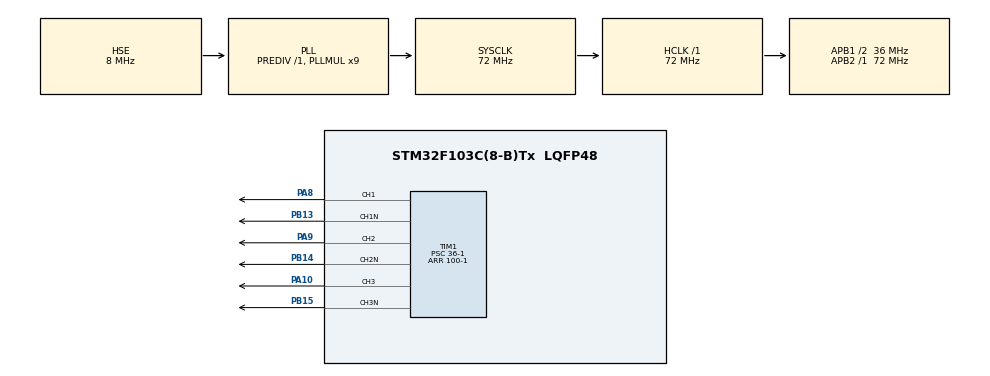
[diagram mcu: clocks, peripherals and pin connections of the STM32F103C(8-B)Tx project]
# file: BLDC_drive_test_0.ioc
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Mcu.Family=STM32F1
Mcu.Name=STM32F103C(8-B)Tx
Mcu.Package=LQFP48
NVIC.PriorityGroup=NVIC_PRIORITYGROUP_4
PA10.Signal=S_TIM1_CH3
PA8.Signal=S_TIM1_CH1
PA9.Signal=S_TIM1_CH2
PB13.Mode=PWM Generation1 CH1 CH1N
PB13.Signal=TIM1_CH1N
PB14.Mode=PWM Generation2 CH2 CH2N
PB14.Signal=TIM1_CH2N
PB15.Mode=PWM Generation3 CH3 CH3N
PB15.Signal=TIM1_CH3N
PD0-OSC_IN.Mode=HSE-External-Oscillator
PD0-OSC_IN.Signal=RCC_OSC_IN
PD1-OSC_OUT.Mode=HSE-External-Oscillator
PD1-OSC_OUT.Signal=RCC_OSC_OUT
ProjectManager.HeapSize=0x200
ProjectManager.StackSize=0x400
ProjectManager.TargetToolchain=MDK-ARM V5
RCC.AHBFreq_Value=72000000
RCC.APB1CLKDivider=RCC_HCLK_DIV2
RCC.APB1Freq_Value=36000000
RCC.APB1TimFreq_Value=72000000
RCC.APB2Freq_Value=72000000
RCC.APB2TimFreq_Value=72000000
RCC.HCLKFreq_Value=72000000
RCC.PLLMUL=RCC_PLL_MUL9
RCC.PLLSourceVirtual=RCC_PLLSOURCE_HSE
RCC.SYSCLKFreq_VALUE=72000000
RCC.SYSCLKSource=RCC_SYSCLKSOURCE_PLLCLK
RCC.USBFreq_Value=72000000
SH.S_TIM1_CH1.0=TIM1_CH1,PWM Generation1 CH1 CH1N
SH.S_TIM1_CH2.0=TIM1_CH2,PWM Generation2 CH2 CH2N
SH.S_TIM1_CH3.0=TIM1_CH3,PWM Generation3 CH3 CH3N
TIM1.AutoReloadPreload=TIM_AUTORELOAD_PRELOAD_ENABLE
TIM1.Channel-PWM\ Generation1\ CH1\ CH1N=TIM_CHANNEL_1
TIM1.Channel-PWM\ Generation2\ CH2\ CH2N=TIM_CHANNEL_2
TIM1.Channel-PWM\ Generation3\ CH3\ CH3N=TIM_CHANNEL_3
TIM1.DeadTime=5
TIM1.Period=100-1
TIM1.Prescaler=36-1
VP_SYS_VS_ND.Mode=No_Debug
VP_TIM1_VS_ClockSourceINT.Mode=Internal
board=custom

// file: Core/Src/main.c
/* USER CODE BEGIN Header */
/**
  ******************************************************************************
  * @file           : main.c
  * @brief          : Main program body
  ******************************************************************************
  * @attention
  *
  * <h2><center>&copy; Copyright (c) 2021 STMicroelectronics.
  * All rights reserved.</center></h2>
  *
  * This software component is licensed by ST under BSD 3-Clause license,
  * the "License"; You may not use this file except in compliance with the
  * License. You may obtain a copy of the License at:
  *                        opensource.org/licenses/BSD-3-Clause
  *
  ******************************************************************************
  */
/* USER CODE END Header */
#include "main.h"
#include "tim.h"
#include "gpio.h"

/* USER CODE BEGIN PTD */
void setPhaseVoltage(float Uq, float Ud, float angle_el);
/* USER CODE END PTD */

/* USER CODE BEGIN PM */
extern float voltage_power_supply;
/* USER CODE END PM */

void SystemClock_Config(void);

int main(void)
{
  /* USER CODE BEGIN 1 */
	float angle_el=0;
  /* USER CODE END 1 */

  /* MCU Configuration--------------------------------------------------------*/

  /* Reset of all peripherals, Initializes the Flash interface and the Systick. */
  HAL_Init();

  /* Configure the system clock */
  SystemClock_Config();

  /* Initialize all configured peripherals */
  MX_GPIO_Init();
  MX_TIM1_Init();
  /* USER CODE BEGIN 2 */
	//输出6路PWM
	HAL_TIM_PWM_Start(&htim1,TIM_CHANNEL_1);
	HAL_TIM_PWM_Start(&htim1,TIM_CHANNEL_2);
	HAL_TIM_PWM_Start(&htim1,TIM_CHANNEL_3);
	HAL_TIMEx_PWMN_Start(&htim1,TIM_CHANNEL_1);
	HAL_TIMEx_PWMN_Start(&htim1,TIM_CHANNEL_2);
	HAL_TIMEx_PWMN_Start(&htim1,TIM_CHANNEL_3);

	voltage_power_supply=24;
  /* USER CODE END 2 */

  /* Infinite loop */
  while (1)
  {
		setPhaseVoltage(1.2,0,angle_el);    //uq<2.
		angle_el=angle_el+0.1;              //估计电角度

  }
}

void SystemClock_Config(void)
{
  RCC_OscInitTypeDef RCC_OscInitStruct = {0};
  RCC_ClkInitTypeDef RCC_ClkInitStruct = {0};

  /** Initializes the RCC Oscillators according to the specified parameters
  * in the RCC_OscInitTypeDef structure.
  */
  RCC_OscInitStruct.OscillatorType = RCC_OSCILLATORTYPE_HSE;
  RCC_OscInitStruct.HSEState = RCC_HSE_ON;
  RCC_OscInitStruct.HSEPredivValue = RCC_HSE_PREDIV_DIV1;
  RCC_OscInitStruct.HSIState = RCC_HSI_ON;
  RCC_OscInitStruct.PLL.PLLState = RCC_PLL_ON;
  RCC_OscInitStruct.PLL.PLLSource = RCC_PLLSOURCE_HSE;
  RCC_OscInitStruct.PLL.PLLMUL = RCC_PLL_MUL9;
  if (HAL_RCC_OscConfig(&RCC_OscInitStruct) != HAL_OK)
  {
    Error_Handler();
  }
  /** Initializes the CPU, AHB and APB buses clocks
  */
  RCC_ClkInitStruct.ClockType = RCC_CLOCKTYPE_HCLK|RCC_CLOCKTYPE_SYSCLK
                              |RCC_CLOCKTYPE_PCLK1|RCC_CLOCKTYPE_PCLK2;
  RCC_ClkInitStruct.SYSCLKSource = RCC_SYSCLKSOURCE_PLLCLK;
  RCC_ClkInitStruct.AHBCLKDivider = RCC_SYSCLK_DIV1;
  RCC_ClkInitStruct.APB1CLKDivider = RCC_HCLK_DIV2;
  RCC_ClkInitStruct.APB2CLKDivider = RCC_HCLK_DIV1;

  if (HAL_RCC_ClockConfig(&RCC_ClkInitStruct, FLASH_LATENCY_2) != HAL_OK)
  {
    Error_Handler();
  }
}

void Error_Handler(void)
{
}

/************************ (C) COPYRIGHT STMicroelectronics *****END OF FILE****/
